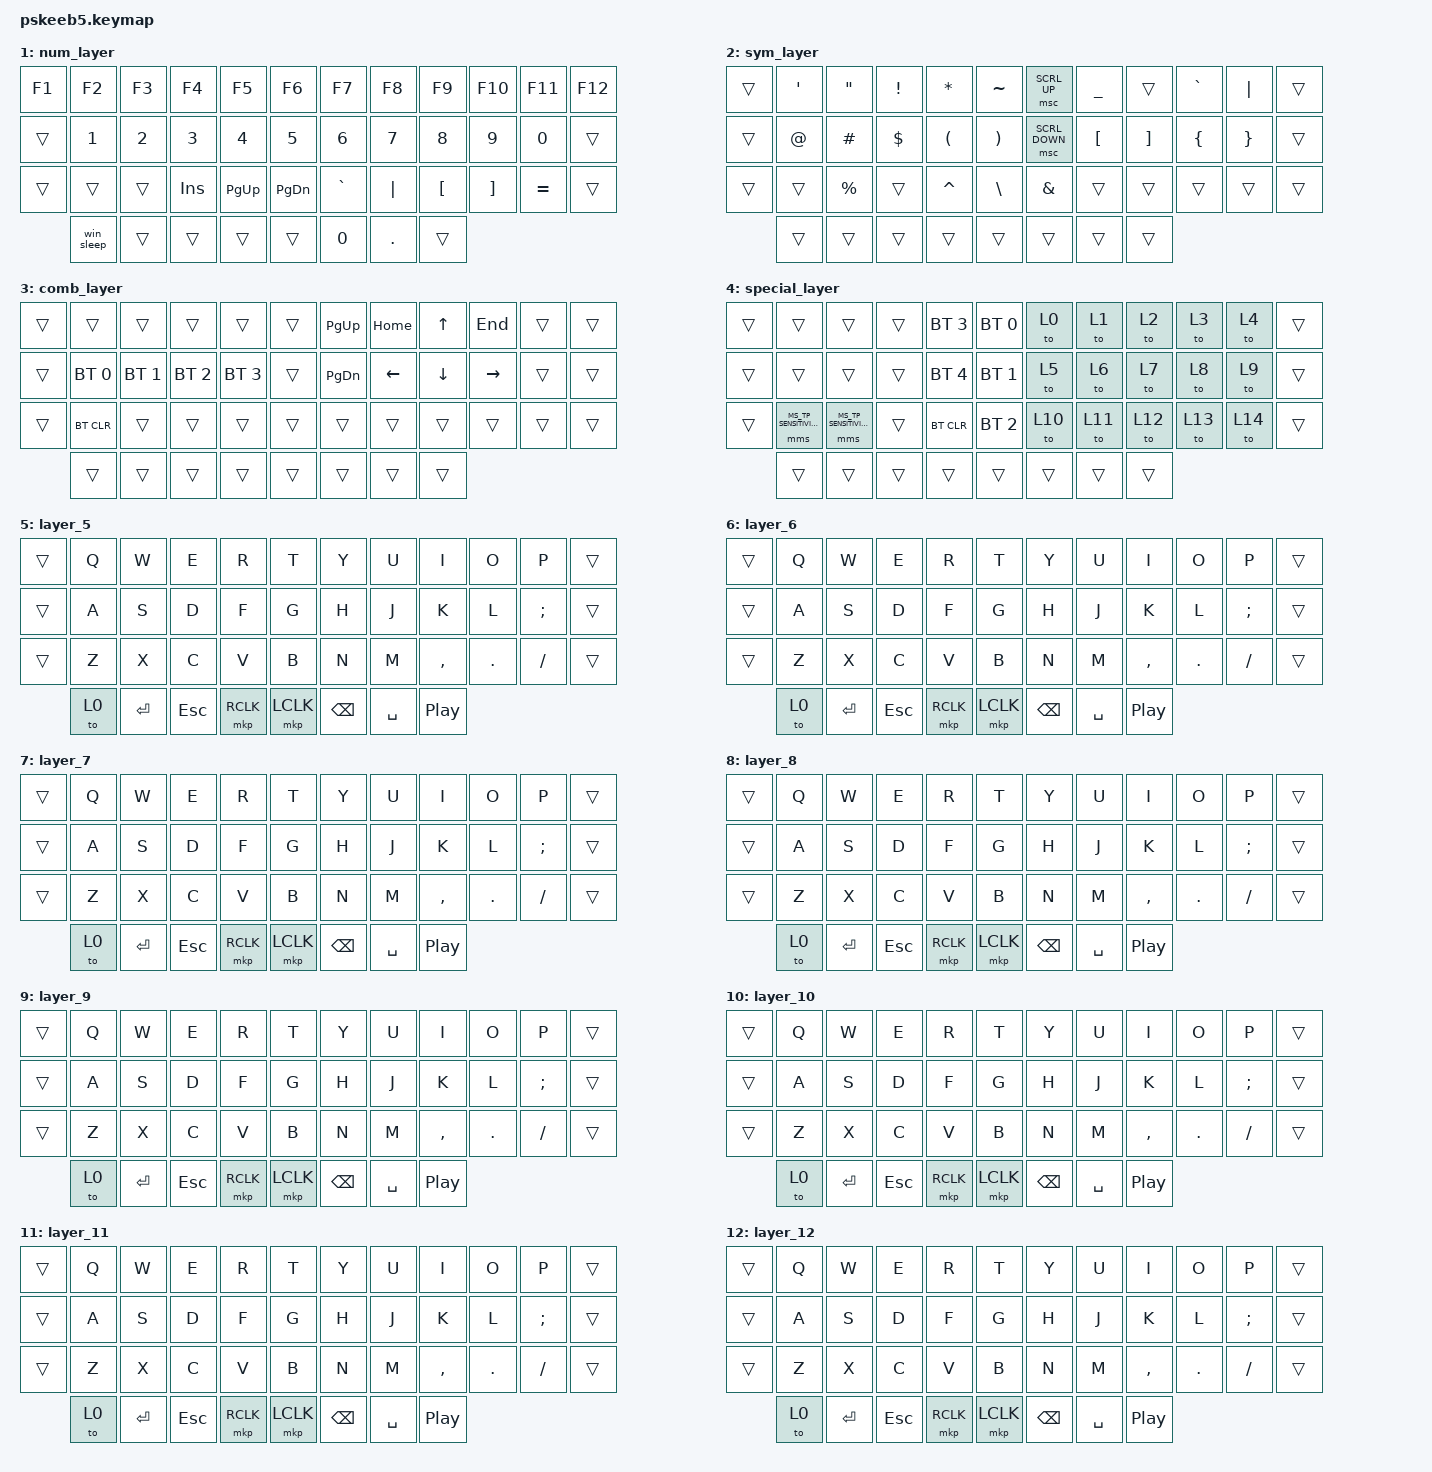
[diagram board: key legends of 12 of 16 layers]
// Copyright (c) 2022 The ZMK Contributors
// SPDX-License-Identifier: MIT

#include <behaviors.dtsi>
#include <dt-bindings/zmk/keys.h>
#include <dt-bindings/zmk/mouse.h>
#include <dt-bindings/zmk/bt.h>

// Home row mods macro
// k1=ring, k2=middle, k3=index -> Alt, Ctrl, Shift (Cmd lives on G/H instead of pinky)
// hml/hmr only treat the OPPOSITE hand's keys as a hold-trigger, so same-hand
// typing (e.g. "bad ", "good") stays tap while cross-hand chords (e.g. D + the
// right-hand space) reliably resolve to hold.
#define HRML(k1,k2,k3) &hml LALT k1  &hml LCTRL k2  &hml LSHFT k3
#define HRMR(k1,k2,k3) &hmr RSHFT k1  &hmr RCTRL k2  &hmr RALT k3
#define LCS(keycode) APPLY_MODS(MOD_LCTL | MOD_LSFT, keycode)
#define LCG(keycode) APPLY_MODS(MOD_LCTL | MOD_LGUI, keycode)

// Rotary Endocer for mouse scrolling
#define ROT_MSC_VAL 280
#define ROT_MSC_SUP MOVE_Y(ROT_MSC_VAL)
#define ROT_MSC_SDN MOVE_Y(-ROT_MSC_VAL)
#define ROT_MSC_SLT MOVE_X(-ROT_MSC_VAL)
#define ROT_MSC_SRT MOVE_X(ROT_MSC_VAL)

// Auto Mouse Layer scroll keys (R/F). Default SCRL_UP/SCRL_DOWN from
// dt-bindings/zmk/mouse.h use ZMK_POINTING_DEFAULT_SCRL_VAL (10 per tick),
// which felt too slow - bumped to 30 (3x) here.
#define MSC_SCRL_VAL 30
#define MSC_SCRL_UP MOVE_Y(MSC_SCRL_VAL)
#define MSC_SCRL_DOWN MOVE_Y(-MSC_SCRL_VAL)


#include <behaviors/mouse_setting.dtsi>
#include <dt-bindings/zmk/mouse_settings.h>
#define U_MSS_TP_S_I &mms MS_TP_SENSITIVITY_INCR
#define U_MSS_TP_S_D &mms MS_TP_SENSITIVITY_DECR

/ {
    behaviors {
        // Left-hand home row mods: right-hand key positions count as a
        // hold-trigger. Both spaces (pos39/40) are included on both hml and
        // hmr - space is a thumb-neutral key hit by either hand, so e.g. D
        // held + either space bar must reliably resolve to hold (Ctrl+Space
        // for IME toggle), not just the "opposite hand" space. Tab (pos0) is
        // included here too (hmr already had it) - it's an OS shortcut
        // target (Alt+Tab/Ctrl+Tab/Shift+Tab) more than a same-hand letter,
        // so e.g. S held + Tab must reliably resolve to hold for Alt+Tab.
        hml: hold_tap_left {
            display-name = "Hold Tap Left";
            label = "HML";
            compatible = "zmk,behavior-hold-tap";
            #binding-cells = <2>;
            flavor = "balanced";
            tapping-term-ms = <220>;
            quick-tap-ms = <200>;
            require-prior-idle-ms = <150>;
            hold-trigger-key-positions = <0 6 7 8 9 10 11 18 19 20 21 22 23 30 31 32 33 34 35 39 40 41 42 43>;
            hold-trigger-on-release;
            bindings = <&kp>, <&kp>;
        };
        // Right-hand home row mods: left-hand key positions count as a
        // hold-trigger, plus both spaces (see hml comment above).
        hmr: hold_tap_right {
            display-name = "Hold Tap Right";
            label = "HMR";
            compatible = "zmk,behavior-hold-tap";
            #binding-cells = <2>;
            flavor = "balanced";
            tapping-term-ms = <220>;
            quick-tap-ms = <200>;
            require-prior-idle-ms = <150>;
            hold-trigger-key-positions = <0 1 2 3 4 5 12 13 14 15 16 17 24 25 26 27 28 29 36 37 38 39 40>;
            hold-trigger-on-release;
            bindings = <&kp>, <&kp>;
        };
        lt: layer_tap {
            display-name = "Layer Tap";
            compatible = "zmk,behavior-hold-tap";
            label = "LAYER_TAP";
            #binding-cells = <2>;
            // flavor = "balanced";
            tapping-term-ms = <200>;
            quick-tap-ms = <200>;
            // global-quick-tap;
            bindings = <&mo>, <&kp>;
        };
        // Same as lt (hold = momentary layer, default hold-preferred flavor)
        // but tap sends a mouse button instead of a keycode. Used on the
        // Auto Mouse Layer's right-click key so holding it acts as the
        // normal Fn/Nav key (see pos41 in mouse_layer) instead of clicking.
        mo_mkp: mo_or_mouse_click {
            display-name = "Momentary Layer or Mouse Click";
            compatible = "zmk,behavior-hold-tap";
            label = "MO_MKP";
            #binding-cells = <2>;
            tapping-term-ms = <200>;
            quick-tap-ms = <200>;
            bindings = <&mo>, <&mkp>;
        };
        rot_msc: sensor_rotate_msc {
            compatible = "zmk,behavior-sensor-rotate-var";
            #sensor-binding-cells = <2>;
            bindings = <&msc>, <&msc>;
            tap-ms = <20>;
        };
    };


    combos {
        compatible = "zmk,combos";
        // NOTE: no E+R -> Tab combo here anymore. Tab already lives directly
        // on pos0, and rolling "er"/"re" while typing kept misfiring the
        // combo and sending a spurious Tab instead of the letters.
        combo_esc {
            timeout-ms = <50>;
            key-positions = <0 1>;
            bindings = <&kp ESC>;
        };
        middle_click {
            timeout-ms = <50>;
            key-positions = <39 40>;
            bindings = <&mkp MCLK>;
        };
        // Direct (non-toggle) IME switching, mirroring the Eisu/Kana keys on
        // a JIS keyboard: LANG2 = Eisu (forces half-width/IME off), LANG1 =
        // Kana (forces full-width/IME on). D+F and J+K are the same-hand
        // home row pairs already used for Ctrl/Shift, chosen so this doesn't
        // collide with any existing cross-hand hold-tap combo.
        combo_hankaku {
            timeout-ms = <50>;
            key-positions = <15 16>;
            bindings = <&kp LANG2>;
        };
        combo_zenkaku {
            timeout-ms = <50>;
            key-positions = <19 20>;
            bindings = <&kp LANG1>;
        };
    };

    conditional_layers {
        compatible = "zmk,conditional-layers";
        special_layer {
            if-layers = <2 3>;
            then-layer = <4>;
        };
    };

    macros {
        win_sleep: win_sleep {
            compatible = "zmk,behavior-macro";
            #binding-cells = <0>;
            bindings
                = <&kp LG(X)>   // Opens the quick menu
                , <&macro_wait_time 50>    // Small delay for menu
                , <&kp U>       // "Shut down or sign out"
                , <&macro_wait_time 50>    // Delay
                , <&kp S>;      // "Sleep"
        };
    };

    keymap {
        compatible = "zmk,keymap";
        default_layer {
            bindings = <
        //╭──────────┬──────────┬──────────┬──────────┬──────────┬──────────╮   ╭──────────┬──────────┬──────────┬──────────┬──────────┬──────────╮
        //│  Tab     │  Q       │  W       │  E       │  R       │  T       │   │  Y       │  U       │  I       │  O       │  P       │  Bksp    │
            &kp TAB    &kp Q      &kp W      &kp E      &kp R      &kp T          &kp Y      &kp U      &kp I      &kp O      &kp P      &kp BSPC
        //├──────────┼──────────┼──────────┼──────────┼──────────┼──────────┤   ├──────────┼──────────┼──────────┼──────────┼──────────┼──────────┤
        //│  Shift   │  A       │  S       │  D       │  F       │  G(Cmd)  │   │  H(Cmd)  │  J       │  K       │  L       │ ; :      │  Enter   │
            &kp LSHFT  &kp A      HRML(S,        D,         F)     &hml LGUI G      &hmr RGUI H HRMR(J,        K,         L)               &kp SEMI  &kp ENTER
        //├──────────┼──────────┼──────────┼──────────┼──────────┼──────────┤   ├──────────┼──────────┼──────────┼──────────┼──────────┼──────────┤
        //│  Ctrl    │  Z       │  X       │  C       │  V       │  B       │   │  N       │  M       │ , <      │ . >      │ ' "      │  - _     │
            &kp LCTRL  HRMR(Z,        X,        C)         &kp V      &kp B          &kp N      &kp M      HRML(COMMA,     DOT,      SQT)    &kp MINUS
        //╰──────────┴──────────┴──────────┴──────────┼──────────┼──────────┤   ├──────────┼──────────┼──────────┴──────────┴──────────┴──────────╯
                       &kp K_POWER  &kp LALT     &kp LGUI   &lt 1 SPACE      &lt 1 SPACE  &mo 3     &kp FSLH   &kp C_PP
        //                                     ╰──────────┴──────────╯   ╰──────────┴──────────╯
            >;
            // Left encoder: vertical scroll / Right encoder: tab switch (Ctrl+Shift+Tab / Ctrl+Tab)
            // Left dial push: wheel click / Right dial push: close tab (Cmd+W)
            sensor-bindings = <&rot_msc ROT_MSC_SUP ROT_MSC_SDN &inc_dec_kp LC(LS(TAB)) LC(TAB)>;
        };

        num_layer {
            bindings = <
        //╭──────────┬──────────┬──────────┬──────────┬──────────┬──────────╮   ╭──────────┬──────────┬──────────┬──────────┬──────────┬──────────╮
        //│ F1       │ F2       │ F3       │ F4       │ F5       │ F6       │   │ F7       │ F8       │ F9       │ F10      │ F11      │ F12      │
            &kp F1     &kp F2     &kp F3     &kp F4     &kp F5     &kp F6         &kp F7     &kp F8     &kp F9     &kp F10    &kp F11    &kp F12
        //├──────────┼──────────┼──────────┼──────────┼──────────┼──────────┤   ├──────────┼──────────┼──────────┼──────────┼──────────┼──────────┤
        //│          │ 1        │ 2        │ 3        │ 4        │ 5        │   │ 6        │ 7        │ 8        │ 9        │ 0        │          │
            &trans     &kp N1     &kp N2     &kp N3     &kp N4     &kp N5         &kp N6     &kp N7     &kp N8     &kp N9     &kp N0     &trans
        //├──────────┼──────────┼──────────┼──────────┼──────────┼──────────┤   ├──────────┼──────────┼──────────┼──────────┼──────────┼──────────┤
        //│          │          │          │ INSERT   │ PAGE UP  │ PAGE DN  │   │ `        │ |        │ [        │ ]        │ =        │          │
            &trans     &trans     &trans     &kp INS    &kp PG_UP  &kp PG_DN      &kp GRAVE  &kp PIPE  &kp LBKT  &kp RBKT  &kp EQUAL  &trans
        //╰──────────┴──────────┴──────────┴──────────┼──────────┼──────────┤   ├──────────┼──────────┼──────────┴──────────┴──────────┴──────────╯
                       &win_sleep  &trans    &trans     &trans         &trans     &kp N0     &kp DOT       &trans
        //                                 ╰──────────┴──────────╯   ╰──────────┴──────────╯
            >;
            sensor-bindings = <&rot_msc ROT_MSC_SUP ROT_MSC_SDN &inc_dec_kp LC(LS(TAB)) LC(TAB)>;
        };

        sym_layer {
            bindings = <
        //╭──────────┬──────────┬──────────┬──────────┬──────────┬──────────╮   ╭────────────┬──────────┬──────────┬──────────┬──────────╮
        //│          │  '       │  "       │  !       │  *       │  ~       │   │ scroll up  │  _       │          │  `       │  |       │
            &trans     &kp SQT     &kp DQT   &kp EXCL   &kp STAR   &kp TILDE      &msc SCRL_UP    &kp UNDER  &trans  &kp GRAVE  &kp PIPE   &trans
        //├──────────┼──────────┼──────────┼──────────┼──────────┼──────────┤   ├────────────┼──────────┼──────────┼──────────┼──────────┤
        //│          │  @       │  #       │  $       │  (       │  )       │   │ scroll down│  [       │  ]       │ {        │  }       │
            &trans     &kp AT     &kp HASH   &kp DLLR   &kp LPAR   &kp RPAR       &msc SCRL_DOWN  &kp LBKT   &kp RBKT  &kp LBRC   &kp RBRC   &trans
        //├──────────┼──────────┼──────────┼──────────┼──────────┼──────────┤   ├────────────┼──────────┼──────────┼──────────┼──────────┤
        //│          │          │  %       │          │ ^        │  \       │   │  &         │          │          │          │          │
            &trans     &trans     &kp PRCNT  &trans     &kp CARET  &kp BSLH       &kp AMPS     &trans     &trans    &trans     &trans      &trans
        //╰──────────┴──────────┴──────────┴──────────┼──────────┼──────────┤   ├────────────┼──────────┼──────────┴──────────┴──────────┴──────────╯
                        &trans     &trans    &trans     &trans         &trans       &trans     &trans     &trans
        //                                 ╰──────────┴──────────╯   ╰────────────┴──────────╯
            >;
            sensor-bindings = <&rot_msc ROT_MSC_SUP ROT_MSC_SDN &inc_dec_kp LC(LS(TAB)) LC(TAB)>;
        };

        comb_layer {
            bindings = <
        //╭──────────┬──────────┬──────────┬──────────┬──────────┬──────────╮   ╭──────────┬──────────┬──────────┬──────────┬──────────┬──────────╮
        //│          │          │          │          │          │          │   │ PageUp   │ Home     │ Up       │ End      │          │          │
            &trans     &trans     &trans     &trans     &trans     &trans         &kp PG_UP  &kp HOME   &kp UP     &kp END    &trans     &trans
        //├──────────┼──────────┼──────────┼──────────┼──────────┼──────────┤   ├──────────┼──────────┼──────────┼──────────┼──────────┼──────────┤
        //│          │ BT 1     │ BT 2     │ BT 3     │ BT 4     │          │   │ PageDown │ Left     │ Down     │ Right    │          │          │
            &trans     &bt BT_SEL 0  &bt BT_SEL 1  &bt BT_SEL 2  &bt BT_SEL 3  &trans      &kp PG_DN  &kp LEFT   &kp DOWN   &kp RIGHT  &trans     &trans
        //├──────────┼──────────┼──────────┼──────────┼──────────┼──────────┤   ├──────────┼──────────┼──────────┼──────────┼──────────┼──────────┤
        //│          │ BT CLEAR │          │          │          │          │   │          │          │          │          │          │          │
            &trans     &bt BT_CLR  &trans     &trans     &trans     &trans         &trans     &trans     &trans     &trans     &trans     &trans
        //╰──────────┴──────────┴──────────┴──────────┼──────────┼──────────┤   ├──────────┼──────────┼──────────┴──────────┴──────────┴──────────╯
                        &trans     &trans    &trans     &trans         &trans       &trans     &trans     &trans
        //                                 ╰──────────┴──────────╯   ╰──────────┴──────────╯
            >;
            sensor-bindings = <&rot_msc ROT_MSC_SUP ROT_MSC_SDN &inc_dec_kp LC(LS(TAB)) LC(TAB)>;
        };

        special_layer {
            bindings = <
        //╭──────────────┬──────────────┬──────────────┬──────────┬─────────────┬────────────╮   ╭──────────┬──────────┬──────────┬──────────┬──────────┬──────────╮
        //│              │              │              │          │ PROFILE 3   │PROFILE 0   │   │          │          │          │          │          │          │
            &trans           &trans           &trans        &trans     &bt BT_SEL 3 &bt BT_SEL 0      &to 0     &to 1       &to 2      &to 3      &to 4      &trans
        //├──────────────┼──────────────┼──────────────┼──────────┼─────────────┼────────────┤   ├──────────┼──────────┼──────────┼──────────┼──────────┼──────────┤
        //│              │              │              │          │ PROFILE 4   │PROFILE 1   │   │          │          │          │          │          │          │
            &trans           &trans           &trans       &trans    &bt BT_SEL 4 &bt BT_SEL 1       &to 5     &to 6       &to 7      &to 8      &to 9      &trans
        //├──────────────┼──────────────┼──────────────┼──────────┼─────────────┼────────────┤   ├──────────┼──────────┼──────────┼──────────┼──────────┼──────────┤
        //│              │              │              │          │ CLEAR BT    │PROFILE 2   │   │          │          │          │          │          │          │
            &trans          U_MSS_TP_S_D    U_MSS_TP_S_I   &trans   &bt BT_CLR   &bt BT_SEL 2        &to 10    &to 11      &to 12     &to 13     &to 14     &trans
        //╰──────────────┴──────────────┴──────────────┴──────────┼─────────────┼────────────┤   ├──────────┼──────────┼──────────┴──────────┴──────────┴──────────╯
                       &trans     &trans    &trans     &trans             &trans     &trans     &trans     &trans
        //                                 ╰─────────────┴──────────╯   ╰──────────┴──────────╯
            >;
            sensor-bindings = <&rot_msc ROT_MSC_SUP ROT_MSC_SDN &inc_dec_kp LC(LS(TAB)) LC(TAB)>;
        };

        layer_5 {
            bindings = <
        //╭──────────┬──────────┬──────────┬──────────┬──────────┬──────────╮   ╭──────────┬──────────┬──────────┬──────────┬──────────┬──────────╮
            &trans     &kp Q      &kp W      &kp E      &kp R      &kp T          &kp Y      &kp U      &kp I      &kp O      &kp P      &trans
        //├──────────┼──────────┼──────────┼──────────┼──────────┼──────────┤   ├──────────┼──────────┼──────────┼──────────┼──────────┼──────────┤
            &trans     &kp A      &kp S      &kp D      &kp F      &kp G          &kp H      &kp J      &kp K      &kp L      &kp SEMI   &trans
        //├──────────┼──────────┼──────────┼──────────┼──────────┼──────────┤   ├──────────┼──────────┼──────────┼──────────┼──────────┼──────────┤
            &trans     &kp Z      &kp X      &kp C      &kp V      &kp B          &kp N      &kp M      &kp COMMA  &kp DOT    &kp FSLH   &trans
        //╰──────────┴──────────┴──────────┴──────────┼──────────┼──────────┤   ├──────────┼──────────┼──────────┴──────────┴──────────┴──────────╯
                       &to 0      &kp ENTER  &kp ESC    &mkp RCLK      &mkp LCLK  &kp BSPC   &kp SPACE  &kp C_PP
        //                                 ╰──────────┴──────────╯   ╰──────────┴──────────╯
            >;
            sensor-bindings = <&rot_msc ROT_MSC_SUP ROT_MSC_SDN &inc_dec_kp LC(LS(TAB)) LC(TAB)>;
        };

        layer_6 {
            bindings = <
        //╭──────────┬──────────┬──────────┬──────────┬──────────┬──────────╮   ╭──────────┬──────────┬──────────┬──────────┬──────────┬──────────╮
            &trans     &kp Q      &kp W      &kp E      &kp R      &kp T          &kp Y      &kp U      &kp I      &kp O      &kp P      &trans
        //├──────────┼──────────┼──────────┼──────────┼──────────┼──────────┤   ├──────────┼──────────┼──────────┼──────────┼──────────┼──────────┤
            &trans     &kp A      &kp S      &kp D      &kp F      &kp G          &kp H      &kp J      &kp K      &kp L      &kp SEMI   &trans
        //├──────────┼──────────┼──────────┼──────────┼──────────┼──────────┤   ├──────────┼──────────┼──────────┼──────────┼──────────┼──────────┤
            &trans     &kp Z      &kp X      &kp C      &kp V      &kp B          &kp N      &kp M      &kp COMMA  &kp DOT    &kp FSLH   &trans
        //╰──────────┴──────────┴──────────┴──────────┼──────────┼──────────┤   ├──────────┼──────────┼──────────┴──────────┴──────────┴──────────╯
                       &to 0      &kp ENTER  &kp ESC    &mkp RCLK      &mkp LCLK  &kp BSPC   &kp SPACE  &kp C_PP
        //                                 ╰──────────┴──────────╯   ╰──────────┴──────────╯
            >;
            sensor-bindings = <&rot_msc ROT_MSC_SUP ROT_MSC_SDN &inc_dec_kp LC(LS(TAB)) LC(TAB)>;
        };

        layer_7 {
            bindings = <
        //╭──────────┬──────────┬──────────┬──────────┬──────────┬──────────╮   ╭──────────┬──────────┬──────────┬──────────┬──────────┬──────────╮
            &trans     &kp Q      &kp W      &kp E      &kp R      &kp T          &kp Y      &kp U      &kp I      &kp O      &kp P      &trans
        //├──────────┼──────────┼──────────┼──────────┼──────────┼──────────┤   ├──────────┼──────────┼──────────┼──────────┼──────────┼──────────┤
            &trans     &kp A      &kp S      &kp D      &kp F      &kp G          &kp H      &kp J      &kp K      &kp L      &kp SEMI   &trans
        //├──────────┼──────────┼──────────┼──────────┼──────────┼──────────┤   ├──────────┼──────────┼──────────┼──────────┼──────────┼──────────┤
            &trans     &kp Z      &kp X      &kp C      &kp V      &kp B          &kp N      &kp M      &kp COMMA  &kp DOT    &kp FSLH   &trans
        //╰──────────┴──────────┴──────────┴──────────┼──────────┼──────────┤   ├──────────┼──────────┼──────────┴──────────┴──────────┴──────────╯
                       &to 0      &kp ENTER  &kp ESC    &mkp RCLK      &mkp LCLK  &kp BSPC   &kp SPACE  &kp C_PP
        //                                 ╰──────────┴──────────╯   ╰──────────┴──────────╯
            >;
            sensor-bindings = <&rot_msc ROT_MSC_SUP ROT_MSC_SDN &inc_dec_kp LC(LS(TAB)) LC(TAB)>;
        };

        layer_8 {
            bindings = <
        //╭──────────┬──────────┬──────────┬──────────┬──────────┬──────────╮   ╭──────────┬──────────┬──────────┬──────────┬──────────┬──────────╮
            &trans     &kp Q      &kp W      &kp E      &kp R      &kp T          &kp Y      &kp U      &kp I      &kp O      &kp P      &trans
        //├──────────┼──────────┼──────────┼──────────┼──────────┼──────────┤   ├──────────┼──────────┼──────────┼──────────┼──────────┼──────────┤
            &trans     &kp A      &kp S      &kp D      &kp F      &kp G          &kp H      &kp J      &kp K      &kp L      &kp SEMI   &trans
        //├──────────┼──────────┼──────────┼──────────┼──────────┼──────────┤   ├──────────┼──────────┼──────────┼──────────┼──────────┼──────────┤
            &trans     &kp Z      &kp X      &kp C      &kp V      &kp B          &kp N      &kp M      &kp COMMA  &kp DOT    &kp FSLH   &trans
        //╰──────────┴──────────┴──────────┴──────────┼──────────┼──────────┤   ├──────────┼──────────┼──────────┴──────────┴──────────┴──────────╯
                       &to 0      &kp ENTER  &kp ESC    &mkp RCLK      &mkp LCLK  &kp BSPC   &kp SPACE  &kp C_PP
        //                                 ╰──────────┴──────────╯   ╰──────────┴──────────╯
            >;
            sensor-bindings = <&rot_msc ROT_MSC_SUP ROT_MSC_SDN &inc_dec_kp LC(LS(TAB)) LC(TAB)>;
        };

        layer_9 {
            bindings = <
        //╭──────────┬──────────┬──────────┬──────────┬──────────┬──────────╮   ╭──────────┬──────────┬──────────┬──────────┬──────────┬──────────╮
            &trans     &kp Q      &kp W      &kp E      &kp R      &kp T          &kp Y      &kp U      &kp I      &kp O      &kp P      &trans
        //├──────────┼──────────┼──────────┼──────────┼──────────┼──────────┤   ├──────────┼──────────┼──────────┼──────────┼──────────┼──────────┤
            &trans     &kp A      &kp S      &kp D      &kp F      &kp G          &kp H      &kp J      &kp K      &kp L      &kp SEMI   &trans
        //├──────────┼──────────┼──────────┼──────────┼──────────┼──────────┤   ├──────────┼──────────┼──────────┼──────────┼──────────┼──────────┤
            &trans     &kp Z      &kp X      &kp C      &kp V      &kp B          &kp N      &kp M      &kp COMMA  &kp DOT    &kp FSLH   &trans
        //╰──────────┴──────────┴──────────┴──────────┼──────────┼──────────┤   ├──────────┼──────────┼──────────┴──────────┴──────────┴──────────╯
                       &to 0      &kp ENTER  &kp ESC    &mkp RCLK      &mkp LCLK  &kp BSPC   &kp SPACE  &kp C_PP
        //                                 ╰──────────┴──────────╯   ╰──────────┴──────────╯
            >;
            sensor-bindings = <&rot_msc ROT_MSC_SUP ROT_MSC_SDN &inc_dec_kp LC(LS(TAB)) LC(TAB)>;
        };

        layer_10 {
            bindings = <
        //╭──────────┬──────────┬──────────┬──────────┬──────────┬──────────╮   ╭──────────┬──────────┬──────────┬──────────┬──────────┬──────────╮
            &trans     &kp Q      &kp W      &kp E      &kp R      &kp T          &kp Y      &kp U      &kp I      &kp O      &kp P      &trans
        //├──────────┼──────────┼──────────┼──────────┼──────────┼──────────┤   ├──────────┼──────────┼──────────┼──────────┼──────────┼──────────┤
            &trans     &kp A      &kp S      &kp D      &kp F      &kp G          &kp H      &kp J      &kp K      &kp L      &kp SEMI   &trans
        //├──────────┼──────────┼──────────┼──────────┼──────────┼──────────┤   ├──────────┼──────────┼──────────┼──────────┼──────────┼──────────┤
            &trans     &kp Z      &kp X      &kp C      &kp V      &kp B          &kp N      &kp M      &kp COMMA  &kp DOT    &kp FSLH   &trans
        //╰──────────┴──────────┴──────────┴──────────┼──────────┼──────────┤   ├──────────┼──────────┼──────────┴──────────┴──────────┴──────────╯
                       &to 0      &kp ENTER  &kp ESC    &mkp RCLK      &mkp LCLK  &kp BSPC   &kp SPACE  &kp C_PP
        //                                 ╰──────────┴──────────╯   ╰──────────┴──────────╯
            >;
            sensor-bindings = <&rot_msc ROT_MSC_SUP ROT_MSC_SDN &inc_dec_kp LC(LS(TAB)) LC(TAB)>;
        };

        layer_11 {
            bindings = <
        //╭──────────┬──────────┬──────────┬──────────┬──────────┬──────────╮   ╭──────────┬──────────┬──────────┬──────────┬──────────┬──────────╮
            &trans     &kp Q      &kp W      &kp E      &kp R      &kp T          &kp Y      &kp U      &kp I      &kp O      &kp P      &trans
        //├──────────┼──────────┼──────────┼──────────┼──────────┼──────────┤   ├──────────┼──────────┼──────────┼──────────┼──────────┼──────────┤
            &trans     &kp A      &kp S      &kp D      &kp F      &kp G          &kp H      &kp J      &kp K      &kp L      &kp SEMI   &trans
        //├──────────┼──────────┼──────────┼──────────┼──────────┼──────────┤   ├──────────┼──────────┼──────────┼──────────┼──────────┼──────────┤
            &trans     &kp Z      &kp X      &kp C      &kp V      &kp B          &kp N      &kp M      &kp COMMA  &kp DOT    &kp FSLH   &trans
        //╰──────────┴──────────┴──────────┴──────────┼──────────┼──────────┤   ├──────────┼──────────┼──────────┴──────────┴──────────┴──────────╯
                       &to 0      &kp ENTER  &kp ESC    &mkp RCLK      &mkp LCLK  &kp BSPC   &kp SPACE  &kp C_PP
        //                                 ╰──────────┴──────────╯   ╰──────────┴──────────╯
            >;
            sensor-bindings = <&rot_msc ROT_MSC_SUP ROT_MSC_SDN &inc_dec_kp LC(LS(TAB)) LC(TAB)>;
        };

        layer_12 {
            bindings = <
        //╭──────────┬──────────┬──────────┬──────────┬──────────┬──────────╮   ╭──────────┬──────────┬──────────┬──────────┬──────────┬──────────╮
            &trans     &kp Q      &kp W      &kp E      &kp R      &kp T          &kp Y      &kp U      &kp I      &kp O      &kp P      &trans
        //├──────────┼──────────┼──────────┼──────────┼──────────┼──────────┤   ├──────────┼──────────┼──────────┼──────────┼──────────┼──────────┤
            &trans     &kp A      &kp S      &kp D      &kp F      &kp G          &kp H      &kp J      &kp K      &kp L      &kp SEMI   &trans
        //├──────────┼──────────┼──────────┼──────────┼──────────┼──────────┤   ├──────────┼──────────┼──────────┼──────────┼──────────┼──────────┤
            &trans     &kp Z      &kp X      &kp C      &kp V      &kp B          &kp N      &kp M      &kp COMMA  &kp DOT    &kp FSLH   &trans
        //╰──────────┴──────────┴──────────┴──────────┼──────────┼──────────┤   ├──────────┼──────────┼──────────┴──────────┴──────────┴──────────╯
                       &to 0      &kp ENTER  &kp ESC    &mkp RCLK      &mkp LCLK  &kp BSPC   &kp SPACE  &kp C_PP
        //                                 ╰──────────┴──────────╯   ╰──────────┴──────────╯
            >;
            sensor-bindings = <&rot_msc ROT_MSC_SUP ROT_MSC_SDN &inc_dec_kp LC(LS(TAB)) LC(TAB)>;
        };

        layer_13 {
            bindings = <
        //╭──────────┬──────────┬──────────┬──────────┬──────────┬──────────╮   ╭──────────┬──────────┬──────────┬──────────┬──────────┬──────────╮
            &trans     &kp Q      &kp W      &kp E      &kp R      &kp T          &kp Y      &kp U      &kp I      &kp O      &kp P      &trans
        //├──────────┼──────────┼──────────┼──────────┼──────────┼──────────┤   ├──────────┼──────────┼──────────┼──────────┼──────────┼──────────┤
            &trans     &kp A      &kp S      &kp D      &kp F      &kp G          &kp H      &kp J      &kp K      &kp L      &kp SEMI   &trans
        //├──────────┼──────────┼──────────┼──────────┼──────────┼──────────┤   ├──────────┼──────────┼──────────┼──────────┼──────────┼──────────┤
            &trans     &kp Z      &kp X      &kp C      &kp V      &kp B          &kp N      &kp M      &kp COMMA  &kp DOT    &kp FSLH   &trans
        //╰──────────┴──────────┴──────────┴──────────┼──────────┼──────────┤   ├──────────┼──────────┼──────────┴──────────┴──────────┴──────────╯
                       &to 0      &kp ENTER  &kp ESC    &mkp RCLK      &mkp LCLK  &kp BSPC   &kp SPACE  &kp C_PP
        //                                 ╰──────────┴──────────╯   ╰──────────┴──────────╯
            >;
            sensor-bindings = <&rot_msc ROT_MSC_SUP ROT_MSC_SDN &inc_dec_kp LC(LS(TAB)) LC(TAB)>;
        };

        layer_14 {
            bindings = <
        //╭──────────┬──────────┬──────────┬──────────┬──────────┬──────────╮   ╭──────────┬──────────┬──────────┬──────────┬──────────┬──────────╮
            &trans     &kp Q      &kp W      &kp E      &kp R      &kp T          &kp Y      &kp U      &kp I      &kp O      &kp P      &trans
        //├──────────┼──────────┼──────────┼──────────┼──────────┼──────────┤   ├──────────┼──────────┼──────────┼──────────┼──────────┼──────────┤
            &trans     &kp A      &kp S      &kp D      &kp F      &kp G          &kp H      &kp J      &kp K      &kp L      &kp SEMI   &trans
        //├──────────┼──────────┼──────────┼──────────┼──────────┼──────────┤   ├──────────┼──────────┼──────────┼──────────┼──────────┼──────────┤
            &trans     &kp Z      &kp X      &kp C      &kp V      &kp B          &kp N      &kp M      &kp COMMA  &kp DOT    &kp FSLH   &trans
        //╰──────────┴──────────┴──────────┴──────────┼──────────┼──────────┤   ├──────────┼──────────┼──────────┴──────────┴──────────┴──────────╯
                       &to 0      &kp ENTER  &kp ESC    &mkp RCLK      &mkp LCLK  &kp BSPC   &kp SPACE  &kp C_PP
        //                                 ╰──────────┴──────────╯   ╰──────────┴──────────╯
            >;
            sensor-bindings = <&rot_msc ROT_MSC_SUP ROT_MSC_SDN &inc_dec_kp LC(LS(TAB)) LC(TAB)>;
        };

        // Auto Mouse Layer: activated automatically by trackpoint movement (see &mouse_ps2_input_listener below)
        // Everything not listed below is &trans (falls through to the base
        // layer) rather than &none, so ordinary typing/modifiers (e.g.
        // holding Alt and tapping Tab repeatedly for app switching) keep
        // working normally while the trackpoint is in use. &none would
        // silently swallow the keypress instead of sending it - it does NOT
        // "pass through" despite looking harmless. Only the pointer buttons
        // and scroll keys below get real overrides.
        mouse_layer {
            bindings = <
        //╭──────────┬──────────┬──────────┬──────────┬──────────┬──────────╮   ╭──────────────┬──────────┬──────────┬──────────┬──────────┬─────────────────╮
        //│          │          │          │          │ SCRL UP  │          │   │              │          │          │          │          │                 │
            &trans     &trans     &trans     &trans     &msc MSC_SCRL_UP  &trans      &trans          &trans      &trans      &trans      &trans      &trans
        //├──────────┼──────────┼──────────┼──────────┼──────────┼──────────┤   ├──────────────┼──────────┼──────────┼──────────┼──────────┼─────────────────┤
        //│          │          │          │          │ SCRL DN  │          │   │              │          │          │          │          │                 │
            &trans     &trans     &trans     &trans     &msc MSC_SCRL_DOWN  &trans    &trans          &trans      &trans      &trans      &trans      &trans
        //├──────────┼──────────┼──────────┼──────────┼──────────┼──────────┤   ├──────────────┼──────────┼──────────┼──────────┼──────────┼─────────────────┤
            &trans     &trans     &trans     &trans     &trans     &trans          &trans          &trans      &trans      &trans      &trans      &trans
        //╰──────────┴──────────┴──────────┴──────────┼──────────┼──────────┤   ├──────────────┼──────────┼──────────┴──────────┴──────────┴─────────────────╯
                       &trans     &trans     &trans     &trans          &mkp LCLK  &mo_mkp 3 RCLK  &mkp MCLK  &trans
        //                                 ╰──────────┴──────────╯   ╰──────────────┴──────────╯
            >;
            sensor-bindings = <&rot_msc ROT_MSC_SUP ROT_MSC_SDN &inc_dec_kp LC(LS(TAB)) LC(TAB)>;
        };
    };
};

#ifdef MOUSE_PS2_DT_PRESENT
// Auto Mouse Layer: enable layer 15 (mouse_layer) while the trackpoint is
// being used, and disable it again after 10s of trackpoint inactivity.
// excluded-positions (from our patched kb_zmk_ps2_mouse_trackpoint_driver
// fork, see config/west.yml): pressing any key position NOT listed here
// while mouse_layer is active deactivates it immediately, without waiting
// for the timeout. pos4/16 (scroll) and pos40 (left click) stay in the
// list so scrolling/dragging keeps the layer active; pos41/42 (right/
// middle click) are intentionally NOT listed, so pressing either one
// exits the Auto Mouse Layer right away - this happens on the physical
// press regardless of how the hold-tap at pos41 (see mo_mkp below)
// eventually resolves, so holding pos41 for Nav-layer navigation (IJKL as
// arrows) also gets a clean exit from the mouse layer first. Any other key
// (e.g. Alt+Tab) still resolves against mouse_layer's own &trans bindings
// for that keypress (ZMK locks in the active layer at press time), so it
// types normally even though the layer itself is already exiting.
&mouse_ps2_input_listener {
    layer-toggle = <15>;
    layer-toggle-timeout-ms = <10000>;
    excluded-positions = <4 16 40>;
};
#endif
